AUTOSAR XML (schema 4-0-3)
standard types defined: Boolean, UInt16, UInt32, UInt8
package /AUTOSAR_Platform/DataConstrs
  range DC_Boolean: raw 0..1
  range DC_UInt16: raw 0..65535
  range DC_UInt8: raw 0..255
package /PATAC/MSM/ComponentTypes
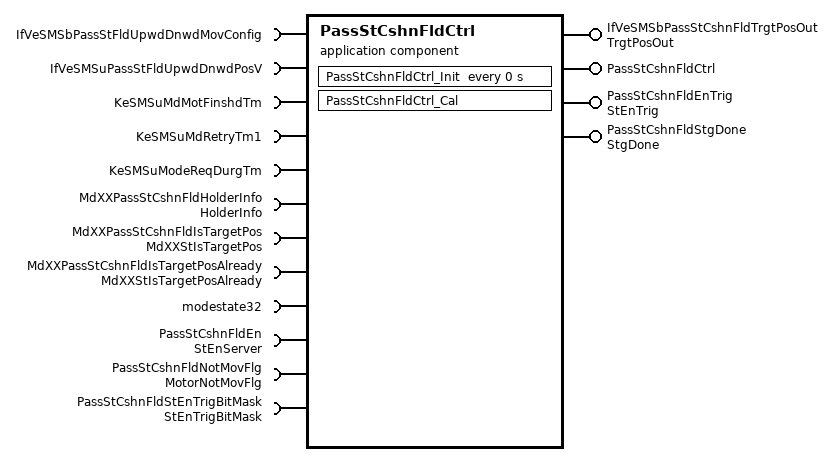
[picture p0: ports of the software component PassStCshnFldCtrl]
  application sw component type PassStCshnFldCtrl
    4 x provide port:
      IfVeSMSbPassStCshnFldTrgtPosOut: nonqueued-sender-com-spec{data-element=TrgtPosOut/Val, init-value=0}, provided-interface=TrgtPosOut
      PassStCshnFldCtrl: server-com-spec{operation=Cal, queue-length=1}, provided-interface=PassStCshnFldCtrl
      PassStCshnFldEnTrig: nonqueued-sender-com-spec{data-element=StEnTrig/Val, init-value=0}, provided-interface=StEnTrig
      PassStCshnFldStgDone: nonqueued-sender-com-spec{data-element=StgDone/Val, init-value=0}, provided-interface=StgDone
    12 x require port:
      IfVeSMSbPassStFldUpwdDnwdMovConfig: nonqueued-receiver-com-spec{data-element=IfVeSMSbPassStFldUpwdDnwdMovConfig/Val, filter=data-filter-type=ALWAYS, init-value=0}, required-interface=IfVeSMSbPassStFldUpwdDnwdMovConfig
      IfVeSMSuPassStFldUpwdDnwdPosV: nonqueued-receiver-com-spec{data-element=IfVeSMSuPassStFldUpwdDnwdPosV/Val, filter=data-filter-type=ALWAYS, init-value=0}, required-interface=IfVeSMSuPassStFldUpwdDnwdPosV
      KeSMSuMdMotFinshdTm: parameter-require-com-spec{init-value=0, parameter=KeSMSuMdMotFinshdTm/Val}, required-interface=KeSMSuMdMotFinshdTm
      KeSMSuMdRetryTm1: parameter-require-com-spec{init-value=0, parameter=KeSMSuMdRetryTm1/Val}, required-interface=KeSMSuMdRetryTm1
      KeSMSuModeReqDurgTm: parameter-require-com-spec{init-value=0, parameter=KeSMSuModeReqDurgTm/Val}, required-interface=KeSMSuModeReqDurgTm
      MdXXPassStCshnFldHolderInfo: nonqueued-receiver-com-spec{data-element=HolderInfo/Val, filter=data-filter-type=ALWAYS, init-value=0}, required-interface=HolderInfo
      MdXXPassStCshnFldIsTargetPos: nonqueued-receiver-com-spec{data-element=MdXXStIsTargetPos/Val, filter=data-filter-type=ALWAYS, init-value=0}, required-interface=MdXXStIsTargetPos
      MdXXPassStCshnFldIsTargetPosAlready: nonqueued-receiver-com-spec{data-element=MdXXStIsTargetPosAlready/Val, filter=data-filter-type=ALWAYS, init-value=0}, required-interface=MdXXStIsTargetPosAlready
      modestate32: nonqueued-receiver-com-spec{data-element=modestate32/Val, filter=data-filter-type=ALWAYS, init-value=0}, required-interface=modestate32
      PassStCshnFldEn: required-com-specs=[Clear, Get, Set], required-interface=StEnServer
      PassStCshnFldNotMovFlg: nonqueued-receiver-com-spec{data-element=MotorNotMovFlg/Val, filter=data-filter-type=ALWAYS, init-value=0}, required-interface=MotorNotMovFlg
      PassStCshnFldStEnTrigBitMask: nonqueued-receiver-com-spec{data-element=StEnTrigBitMask/Val, filter=data-filter-type=ALWAYS, init-value=0}, required-interface=StEnTrigBitMask
    behavior PassStCshnFldCtrl_InternalBehavior
      operation invoked event OIT_PassStCshnFldCtrl_Cal_PassStCshnFldCtrl_Cal: start-on-event=PassStCshnFldCtrl_Cal, operation=PassStCshnFldCtrl.Cal
      timing event PassStCshnFldCtrl_InitEvent: start-on-event=PassStCshnFldCtrl_Init, period=0
      runnable PassStCshnFldCtrl_Cal
        data-receive-point-by-arguments:
          8 x access:
            REC_IfVeSMSbPassStFldUpwdDnwdMovConfig_Val: accessed-variable=IfVeSMSbPassStFldUpwdDnwdMovConfig.Val
            REC_IfVeSMSuPassStFldUpwdDnwdPosV_Val: accessed-variable=IfVeSMSuPassStFldUpwdDnwdPosV.Val
            REC_MdXXPassStCshnFldHolderInfo_Val: accessed-variable=MdXXPassStCshnFldHolderInfo.Val
            REC_MdXXPassStCshnFldIsTargetPos_Val: accessed-variable=MdXXPassStCshnFldIsTargetPos.Val
            REC_MdXXPassStCshnFldIsTargetPosAlready_Val: accessed-variable=MdXXPassStCshnFldIsTargetPosAlready.Val
            REC_modestate32_Val: accessed-variable=modestate32.Val
            REC_PassStCshnFldNotMovFlg_Val: accessed-variable=PassStCshnFldNotMovFlg.Val
            REC_PassStCshnFldStEnTrigBitMask_Val: accessed-variable=PassStCshnFldStEnTrigBitMask.Val
        data-send-points:
          access SEND_IfVeSMSbPassStCshnFldTrgtPosOut_Val: accessed-variable=IfVeSMSbPassStCshnFldTrgtPosOut.Val
          access SEND_PassStCshnFldEnTrig_Val: accessed-variable=PassStCshnFldEnTrig.Val
          access SEND_PassStCshnFldStgDone_Val: accessed-variable=PassStCshnFldStgDone.Val
        parameter access PA_KeSMSuMdMotFinshdTm_Val: accessed-parameter=KeSMSuMdMotFinshdTm.Val
        parameter access PA_KeSMSuMdRetryTm1_Val: accessed-parameter=KeSMSuMdRetryTm1.Val
        parameter access PA_KeSMSuModeReqDurgTm_Val: accessed-parameter=KeSMSuModeReqDurgTm.Val
        sync call SC_PassStCshnFldEn_Get: operation=PassStCshnFldEn.Get, timeout=0
      runnable PassStCshnFldCtrl_Init
        parameter access PA_KeSMSuMdMotFinshdTm_Val: accessed-parameter=KeSMSuMdMotFinshdTm.Val
        parameter access PA_KeSMSuMdRetryTm1_Val: accessed-parameter=KeSMSuMdRetryTm1.Val
        parameter access PA_KeSMSuModeReqDurgTm_Val: accessed-parameter=KeSMSuModeReqDurgTm.Val
  swc implementation PassStCshnFldCtrl_Implementation: behavior=PassStCshnFldCtrl_InternalBehavior
    code-descriptors:
      code Default: artifact-descriptors=autosar-engineering-object={short-label=Default, category=SWSRC}
package /PATAC/MSM/ModeAdjust/CalPortInterface
  parameter interface KeSMSuMdMotFinshdTm
    parameter data prototype Val: sw-calibration-access=READ-WRITE, type=UInt16
  parameter interface KeSMSuModeReqDurgTm
    parameter data prototype Val: sw-calibration-access=READ-WRITE, type=UInt16
package /PATAC/MSM/ModeAdjust/Interfaces
  sender receiver interface IfVeSMSuPassStFldUpwdDnwdPosV: invalidation-policy{data-element=IfVeSMSuPassStFldUpwdDnwdPosV/Val, handle-invalid=DONT-INVALIDATE}
    data Val: type=Boolean
package /PATAC/MSM/ModeAdjust/PortInterface
  client server interface PassStCshnFldCtrl
    operation Cal
  client server interface StEnServer
    operation Clear
      arg data: type=UInt8, direction=IN, server-argument-impl-policy=USE-ARGUMENT-TYPE
    operation Get
      arg data: type=UInt32, direction=OUT, server-argument-impl-policy=USE-ARGUMENT-TYPE
    operation Set
      arg data: type=UInt8, direction=IN, server-argument-impl-policy=USE-ARGUMENT-TYPE
  10 x sender receiver interface:
    HolderInfo: invalidation-policy{data-element=HolderInfo/Val, handle-invalid=DONT-INVALIDATE}
      data Val: type=UInt32
    IfVeSMSbPassStFldUpwdDnwdMovConfig: invalidation-policy{data-element=IfVeSMSbPassStFldUpwdDnwdMovConfig/Val, handle-invalid=DONT-INVALIDATE}
      data Val: type=Boolean
    MdXXStIsTargetPos: invalidation-policy{data-element=MdXXStIsTargetPos/Val, handle-invalid=DONT-INVALIDATE}
      data Val: type=UInt32
    MdXXStIsTargetPosAlready: invalidation-policy{data-element=MdXXStIsTargetPosAlready/Val, handle-invalid=DONT-INVALIDATE}
      data Val: type=UInt32
    modestate32: invalidation-policy{data-element=modestate32/Val, handle-invalid=DONT-INVALIDATE}
      data Val: type=UInt32
    MotorNotMovFlg: invalidation-policy{data-element=MotorNotMovFlg/Val, handle-invalid=DONT-INVALIDATE}
      data Val: type=Boolean
    StEnTrig: invalidation-policy{data-element=StEnTrig/Val, handle-invalid=DONT-INVALIDATE}
      data Val: type=Boolean
    StEnTrigBitMask: invalidation-policy{data-element=StEnTrigBitMask/Val, handle-invalid=DONT-INVALIDATE}
      data Val: type=UInt32
    StgDone: invalidation-policy{data-element=StgDone/Val, handle-invalid=DONT-INVALIDATE}
      data Val: type=Boolean
    TrgtPosOut: invalidation-policy{data-element=TrgtPosOut/Val, handle-invalid=DONT-INVALIDATE}
      data Val: type=Boolean
package /PATAC/MSM/PortInterfaces
  parameter interface KeSMSuMdRetryTm1
    parameter data prototype Val: sw-calibration-access=READ-WRITE, type=UInt8
